AUTOSAR XML (schema 4-0-3)
package /ComponentTypes
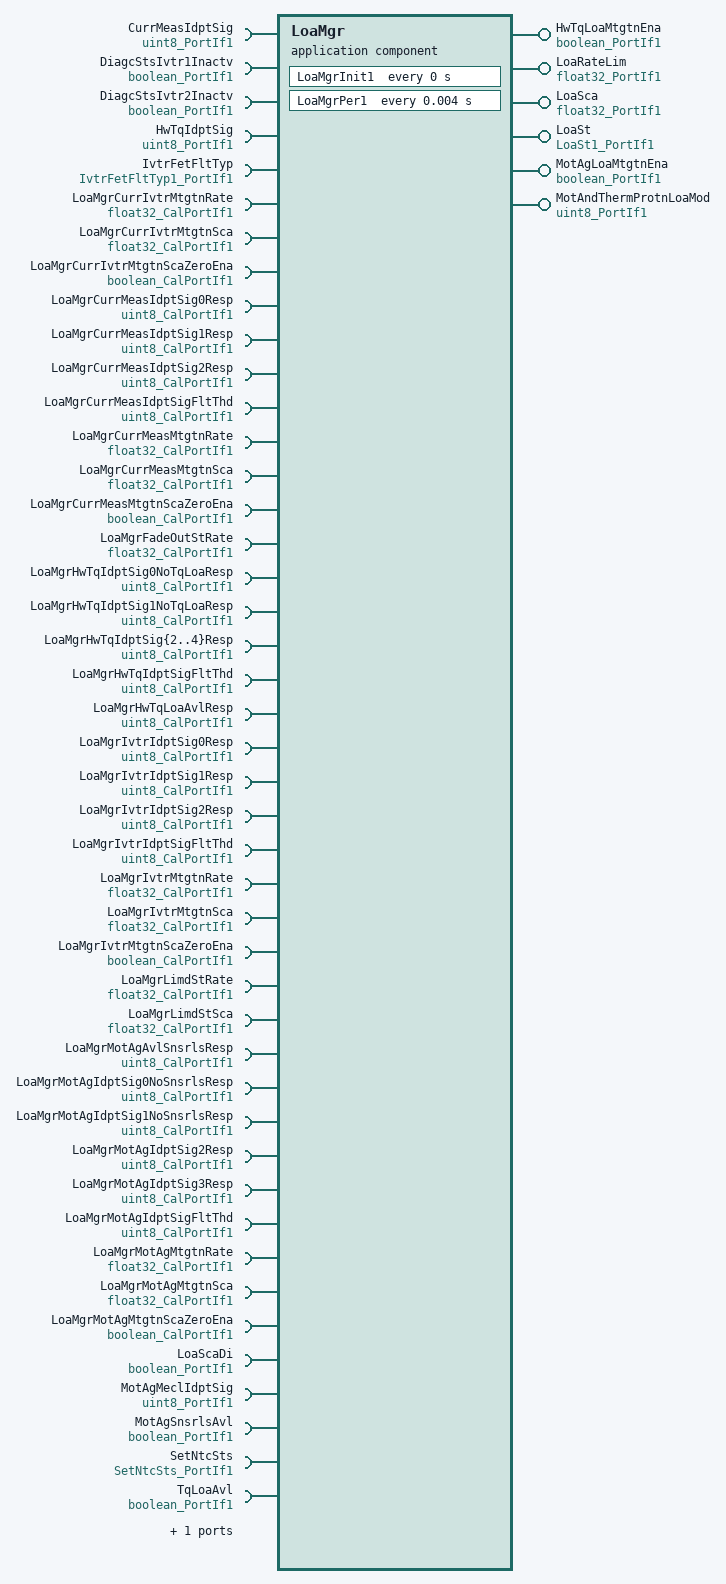
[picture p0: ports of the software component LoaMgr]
  application sw component type LoaMgr
    6 x provide port:
      HwTqLoaMtgtnEna: nonqueued-sender-com-spec{data-element=Logl, init-value=0}, provided-interface=boolean_PortIf1
      LoaRateLim: nonqueued-sender-com-spec{data-element=Val, init-value=1}, provided-interface=float32_PortIf1
      LoaSca: nonqueued-sender-com-spec{data-element=Val, init-value=1}, provided-interface=float32_PortIf1
      LoaSt: nonqueued-sender-com-spec{data-element=Val, init-value=0}, provided-interface=LoaSt1_PortIf1
      MotAgLoaMtgtnEna: nonqueued-sender-com-spec{data-element=Logl, init-value=0}, provided-interface=boolean_PortIf1
      MotAndThermProtnLoaMod: nonqueued-sender-com-spec{data-element=Val, init-value=0}, provided-interface=uint8_PortIf1
    47 x require port:
      CurrMeasIdptSig: nonqueued-receiver-com-spec{data-element=Val, filter=data-filter-type=ALWAYS, init-value=2}, required-interface=uint8_PortIf1
      DiagcStsIvtr1Inactv: nonqueued-receiver-com-spec{data-element=Logl, filter=data-filter-type=ALWAYS, init-value=0}, required-interface=boolean_PortIf1
      DiagcStsIvtr2Inactv: nonqueued-receiver-com-spec{data-element=Logl, filter=data-filter-type=ALWAYS, init-value=0}, required-interface=boolean_PortIf1
      HwTqIdptSig: nonqueued-receiver-com-spec{data-element=Val, filter=data-filter-type=ALWAYS, init-value=4}, required-interface=uint8_PortIf1
      IvtrFetFltTyp: nonqueued-receiver-com-spec{data-element=Val, filter=data-filter-type=ALWAYS, init-value=0}, required-interface=IvtrFetFltTyp1_PortIf1
      LoaMgrCurrIvtrMtgtnRate: parameter-require-com-spec{init-value=1, parameter=Val}, required-interface=float32_CalPortIf1
      LoaMgrCurrIvtrMtgtnSca: parameter-require-com-spec{init-value=1, parameter=Val}, required-interface=float32_CalPortIf1
      LoaMgrCurrIvtrMtgtnScaZeroEna: parameter-require-com-spec{init-value=0, parameter=Logl}, required-interface=boolean_CalPortIf1
      LoaMgrCurrMeasIdptSig0Resp: parameter-require-com-spec{init-value=2, parameter=Val}, required-interface=uint8_CalPortIf1
      LoaMgrCurrMeasIdptSig1Resp: parameter-require-com-spec{init-value=0, parameter=Val}, required-interface=uint8_CalPortIf1
      LoaMgrCurrMeasIdptSig2Resp: parameter-require-com-spec{init-value=0, parameter=Val}, required-interface=uint8_CalPortIf1
      LoaMgrCurrMeasIdptSigFltThd: parameter-require-com-spec{init-value=0, parameter=Val}, required-interface=uint8_CalPortIf1
      LoaMgrCurrMeasMtgtnRate: parameter-require-com-spec{init-value=1, parameter=Val}, required-interface=float32_CalPortIf1
      LoaMgrCurrMeasMtgtnSca: parameter-require-com-spec{init-value=1, parameter=Val}, required-interface=float32_CalPortIf1
      LoaMgrCurrMeasMtgtnScaZeroEna: parameter-require-com-spec{init-value=1, parameter=Logl}, required-interface=boolean_CalPortIf1
      LoaMgrFadeOutStRate: parameter-require-com-spec{init-value=1, parameter=Val}, required-interface=float32_CalPortIf1
      LoaMgrHwTqIdptSig0NoTqLoaResp: parameter-require-com-spec{init-value=4, parameter=Val}, required-interface=uint8_CalPortIf1
      LoaMgrHwTqIdptSig1NoTqLoaResp: parameter-require-com-spec{init-value=4, parameter=Val}, required-interface=uint8_CalPortIf1
      LoaMgrHwTqIdptSig{2..4}Resp: parameter-require-com-spec{init-value=0, parameter=Val}, required-interface=uint8_CalPortIf1
      LoaMgrHwTqIdptSigFltThd: parameter-require-com-spec{init-value=1, parameter=Val}, required-interface=uint8_CalPortIf1
      LoaMgrHwTqLoaAvlResp: parameter-require-com-spec{init-value=2, parameter=Val}, required-interface=uint8_CalPortIf1
      LoaMgrIvtrIdptSig0Resp: parameter-require-com-spec{init-value=5, parameter=Val}, required-interface=uint8_CalPortIf1
      LoaMgrIvtrIdptSig1Resp: parameter-require-com-spec{init-value=2, parameter=Val}, required-interface=uint8_CalPortIf1
      LoaMgrIvtrIdptSig2Resp: parameter-require-com-spec{init-value=0, parameter=Val}, required-interface=uint8_CalPortIf1
      LoaMgrIvtrIdptSigFltThd: parameter-require-com-spec{init-value=0, parameter=Val}, required-interface=uint8_CalPortIf1
      LoaMgrIvtrMtgtnRate: parameter-require-com-spec{init-value=1, parameter=Val}, required-interface=float32_CalPortIf1
      LoaMgrIvtrMtgtnSca: parameter-require-com-spec{init-value=1, parameter=Val}, required-interface=float32_CalPortIf1
      LoaMgrIvtrMtgtnScaZeroEna: parameter-require-com-spec{init-value=0, parameter=Logl}, required-interface=boolean_CalPortIf1
      LoaMgrLimdStRate: parameter-require-com-spec{init-value=1, parameter=Val}, required-interface=float32_CalPortIf1
      LoaMgrLimdStSca: parameter-require-com-spec{init-value=1, parameter=Val}, required-interface=float32_CalPortIf1
      LoaMgrMotAgAvlSnsrlsResp: parameter-require-com-spec{init-value=2, parameter=Val}, required-interface=uint8_CalPortIf1
      LoaMgrMotAgIdptSig0NoSnsrlsResp: parameter-require-com-spec{init-value=5, parameter=Val}, required-interface=uint8_CalPortIf1
      LoaMgrMotAgIdptSig1NoSnsrlsResp: parameter-require-com-spec{init-value=5, parameter=Val}, required-interface=uint8_CalPortIf1
      LoaMgrMotAgIdptSig2Resp: parameter-require-com-spec{init-value=1, parameter=Val}, required-interface=uint8_CalPortIf1
      LoaMgrMotAgIdptSig3Resp: parameter-require-com-spec{init-value=0, parameter=Val}, required-interface=uint8_CalPortIf1
      LoaMgrMotAgIdptSigFltThd: parameter-require-com-spec{init-value=2, parameter=Val}, required-interface=uint8_CalPortIf1
      LoaMgrMotAgMtgtnRate: parameter-require-com-spec{init-value=1, parameter=Val}, required-interface=float32_CalPortIf1
      LoaMgrMotAgMtgtnSca: parameter-require-com-spec{init-value=1, parameter=Val}, required-interface=float32_CalPortIf1
      LoaMgrMotAgMtgtnScaZeroEna: parameter-require-com-spec{init-value=0, parameter=Logl}, required-interface=boolean_CalPortIf1
      LoaScaDi: nonqueued-receiver-com-spec{data-element=Logl, filter=data-filter-type=ALWAYS, init-value=0}, required-interface=boolean_PortIf1
      MotAgMeclIdptSig: nonqueued-receiver-com-spec{data-element=Val, filter=data-filter-type=ALWAYS, init-value=3}, required-interface=uint8_PortIf1
      MotAgSnsrlsAvl: nonqueued-receiver-com-spec{data-element=Logl, filter=data-filter-type=ALWAYS, init-value=0}, required-interface=boolean_PortIf1
      SetNtcSts: client-com-spec=Oper, required-interface=SetNtcSts_PortIf1
      TqLoaAvl: nonqueued-receiver-com-spec{data-element=Logl, filter=data-filter-type=ALWAYS, init-value=0}, required-interface=boolean_PortIf1
      VehSteerMod: nonqueued-receiver-com-spec{data-element=Val, filter=data-filter-type=ALWAYS, init-value=0}, required-interface=SteerMod1_PortIf1
    behavior LoaMgr_InternalBehavior
      exclusive area LoaMgrExclusiveArea
      ar-typed-per-instance-memorys:
        14 x data, all with sw-calibration-access=READ-ONLY:
          PrevCurrMeasIdptSigResp: type=uint8
          PrevCurrMeasIdptSigVal: type=uint8
          PrevCurrMeasLoaStSwMtgtnEna: type=boolean
          PrevHwTqIdptSigResp: type=uint8
          PrevHwTqIdptSigVal: type=uint8
          PrevHwTqLoaStSwMtgtnEna: type=boolean
          PrevIvtrIdptSigResp: type=uint8
          PrevIvtrIdptSigVal: type=uint8
          PrevIvtrLoaStSwMtgtnEna: type=boolean
          PrevMotAgLoaMtgtnEna: type=boolean
          PrevMotAgLoaStSwMtgtnEna: type=boolean
          PrevMotAgMeclIdptSigResp: type=uint8
          PrevMotAgMeclIdptSigVal: type=uint8
          PrevVltgModSrc: type=uint8
      timing event LoaMgr_InitEvent: start-on-event=LoaMgrInit1, period=0
      timing event TMT_LoaMgrPer1: start-on-event=LoaMgrPer1, period=0.004
      port-api-options:
        enable-take-address=false, indirect-api=false, port=LoaMgrHwTqIdptSig4Resp
        enable-take-address=false, indirect-api=false, port=LoaMgrHwTqLoaAvlResp
        enable-take-address=false, indirect-api=false, port=LoaMgrIvtrIdptSig1Resp
        enable-take-address=false, indirect-api=false, port=LoaMgrIvtrIdptSig2Resp
        enable-take-address=false, indirect-api=false, port=LoaMgrIvtrIdptSigFltThd
        enable-take-address=false, indirect-api=false, port=LoaMgrIvtrMtgtnRate
        enable-take-address=false, indirect-api=false, port=LoaMgrIvtrMtgtnSca
        enable-take-address=false, indirect-api=false, port=LoaMgrIvtrMtgtnScaZeroEna
        enable-take-address=false, indirect-api=false, port=LoaMgrLimdStRate
        enable-take-address=false, indirect-api=false, port=LoaMgrLimdStSca
        enable-take-address=false, indirect-api=false, port=LoaMgrMotAgAvlSnsrlsResp
        enable-take-address=false, indirect-api=false, port=LoaMgrMotAgIdptSig0NoSnsrlsResp
        enable-take-address=false, indirect-api=false, port=LoaMgrMotAgIdptSig1NoSnsrlsResp
        enable-take-address=false, indirect-api=false, port=LoaMgrMotAgIdptSig2Resp
        enable-take-address=false, indirect-api=false, port=LoaMgrMotAgIdptSig3Resp
        enable-take-address=false, indirect-api=false, port=LoaMgrMotAgIdptSigFltThd
        enable-take-address=false, indirect-api=false, port=LoaMgrMotAgMtgtnRate
        enable-take-address=false, indirect-api=false, port=LoaMgrMotAgMtgtnSca
        enable-take-address=false, indirect-api=false, port=LoaMgrMotAgMtgtnScaZeroEna
        enable-take-address=false, indirect-api=false, port=LoaRateLim
        enable-take-address=false, indirect-api=false, port=LoaSca
        enable-take-address=false, indirect-api=false, port=LoaScaDi
        enable-take-address=false, indirect-api=false, port=LoaSt
        enable-take-address=false, indirect-api=false, port=MotAgLoaMtgtnEna
        enable-take-address=false, indirect-api=false, port=MotAgMeclIdptSig
        enable-take-address=false, indirect-api=false, port=MotAgSnsrlsAvl
        enable-take-address=false, indirect-api=false, port=SetNtcSts
        enable-take-address=false, indirect-api=false, port=TqLoaAvl
        enable-take-address=false, indirect-api=false, port=VehSteerMod
      runnable LoaMgrInit1
        sync call SC_SetNtcSts_Oper: operation=SetNtcSts.Oper, timeout=0
      runnable LoaMgrPer1: can-enter-exclusive-area=LoaMgrExclusiveArea
        data-receive-point-by-arguments:
          10 x access:
            REC_CurrMeasIdptSig_Val: accessed-variable=CurrMeasIdptSig.Val
            REC_DiagcStsIvtr1Inactv_Logl: accessed-variable=DiagcStsIvtr1Inactv.Logl
            REC_DiagcStsIvtr2Inactv_Logl: accessed-variable=DiagcStsIvtr2Inactv.Logl
            REC_HwTqIdptSig_Val: accessed-variable=HwTqIdptSig.Val
            REC_IvtrFetFltTyp_Val: accessed-variable=IvtrFetFltTyp.Val
            REC_LoaScaDi_Logl: accessed-variable=LoaScaDi.Logl
            REC_MotAgMeclIdptSig_Val: accessed-variable=MotAgMeclIdptSig.Val
            REC_MotAgSnsrlsAvl_Logl: accessed-variable=MotAgSnsrlsAvl.Logl
            REC_TqLoaAvl_Logl: accessed-variable=TqLoaAvl.Logl
            REC_VehSteerMod_Val: accessed-variable=VehSteerMod.Val
        data-send-points:
          6 x access:
            SEND_HwTqLoaMtgtnEna_Logl: accessed-variable=HwTqLoaMtgtnEna.Logl
            SEND_LoaRateLim_Val: accessed-variable=LoaRateLim.Val
            SEND_LoaSca_Val: accessed-variable=LoaSca.Val
            SEND_LoaSt_Val: accessed-variable=LoaSt.Val
            SEND_MotAgLoaMtgtnEna_Logl: accessed-variable=MotAgLoaMtgtnEna.Logl
            SEND_MotAndThermProtnLoaMod_Val: accessed-variable=MotAndThermProtnLoaMod.Val
        sync call SC_SetNtcSts_Oper: operation=SetNtcSts.Oper, timeout=0
  swc implementation LoaMgr_Implementation: behavior=LoaMgr_InternalBehavior
    code-descriptors:
      code Default: artifact-descriptors=autosar-engineering-object={short-label=Default, category=SWSRC}
